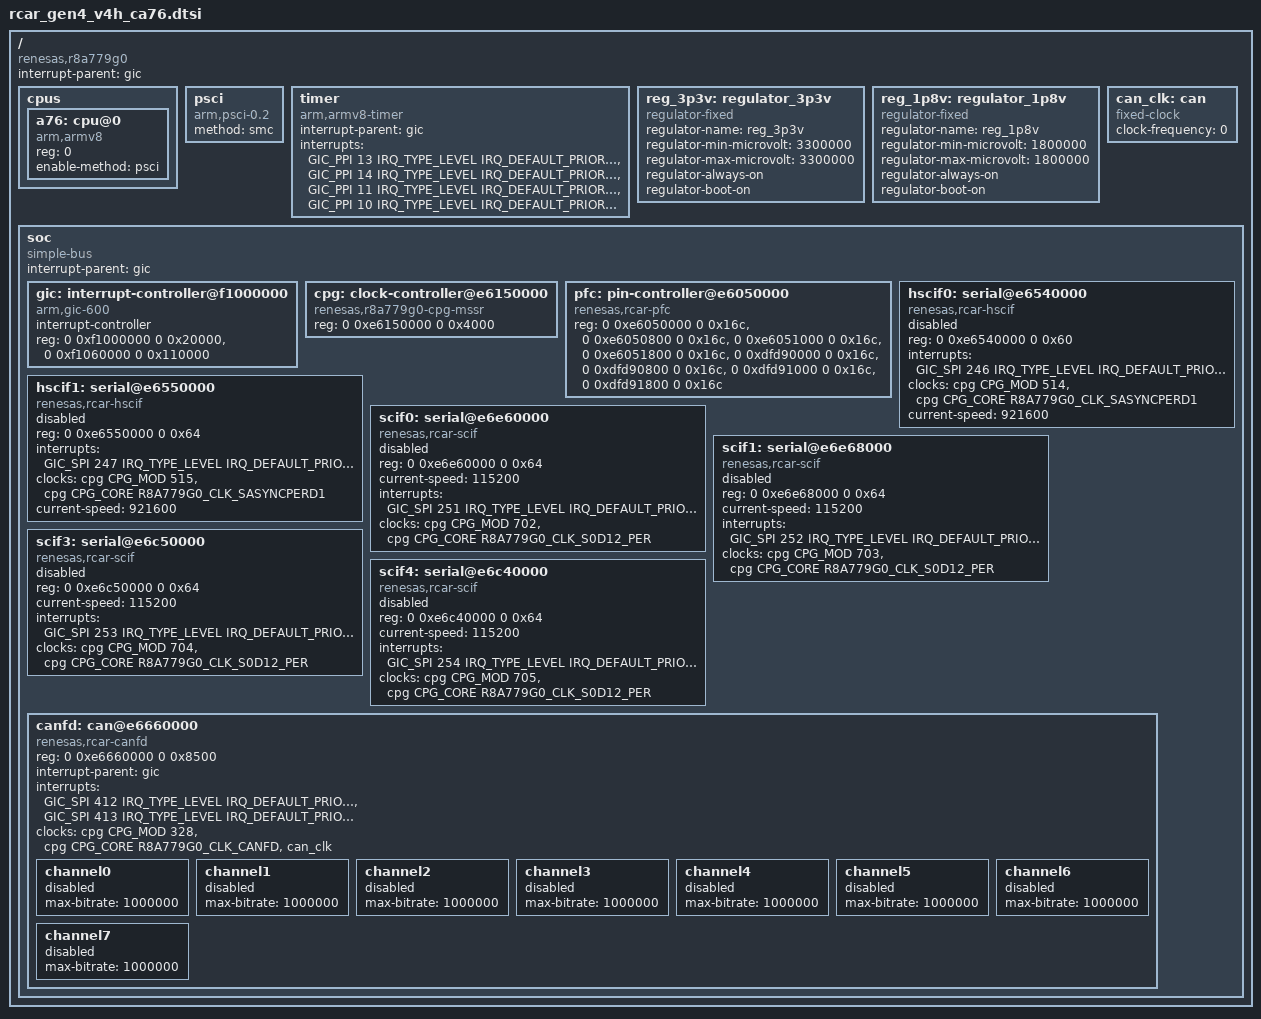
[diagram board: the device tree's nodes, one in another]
/*
 * Copyright (c) 2025 Renesas Electronics Corporation
 *
 * SPDX-License-Identifier: Apache-2.0
 */

#include <mem.h>
#include <arm64/armv8-a.dtsi>
#include <zephyr/dt-bindings/interrupt-controller/arm-gic.h>
#include <zephyr/dt-bindings/clock/renesas_cpg_mssr.h>
#include <zephyr/dt-bindings/clock/r8a779g0_cpg_mssr.h>

/ {
	compatible = "renesas,r8a779g0";
	#address-cells = <2>;
	#size-cells = <2>;
	interrupt-parent = <&gic>;

	cpus {
		#address-cells = <1>;
		#size-cells = <0>;

		a76: cpu@0 {
			device_type = "cpu";
			compatible = "arm,armv8";
			reg = <0>;
			enable-method = "psci";
		};
	};

	psci {
		compatible = "arm,psci-0.2";
		method = "smc";
	};

	timer {
		compatible = "arm,armv8-timer";
		interrupt-parent = <&gic>;
		interrupts = <GIC_PPI 13 IRQ_TYPE_LEVEL IRQ_DEFAULT_PRIORITY>,
			     <GIC_PPI 14 IRQ_TYPE_LEVEL IRQ_DEFAULT_PRIORITY>,
			     <GIC_PPI 11 IRQ_TYPE_LEVEL IRQ_DEFAULT_PRIORITY>,
			     <GIC_PPI 10 IRQ_TYPE_LEVEL IRQ_DEFAULT_PRIORITY>;
	};

	reg_3p3v: regulator_3p3v {
		compatible = "regulator-fixed";
		regulator-name = "reg_3p3v";
		regulator-min-microvolt = <3300000>;
		regulator-max-microvolt = <3300000>;
		regulator-always-on;
		regulator-boot-on;
		status = "okay";
	};

	reg_1p8v: regulator_1p8v {
		compatible = "regulator-fixed";
		regulator-name = "reg_1p8v";
		regulator-min-microvolt = <1800000>;
		regulator-max-microvolt = <1800000>;
		regulator-always-on;
		regulator-boot-on;
		status = "okay";
	};

	can_clk: can {
		compatible = "fixed-clock";
		#clock-cells = <0>;
		clock-frequency = <0>;
	};

	soc: soc {
		compatible = "simple-bus";
		interrupt-parent = <&gic>;

		#address-cells = <2>;
		#size-cells = <2>;
		ranges;

		gic: interrupt-controller@f1000000 {
			compatible = "arm,gic-600", "arm,gic-v3", "arm,gic";
			#interrupt-cells = <4>;
			#address-cells = <0>;
			interrupt-controller;
			reg = <0 0xf1000000 0 0x20000>,
			      <0 0xf1060000 0 0x110000>;
			status = "okay";
		};

		cpg: clock-controller@e6150000 {
			compatible = "renesas,r8a779g0-cpg-mssr";
			reg = <0 0xe6150000 0 0x4000>;
			#clock-cells = <2>;
			#power-domain-cells = <0>;
			#reset-cells = <1>;
		};

		pfc: pin-controller@e6050000 {
			compatible = "renesas,rcar-pfc";
			reg = <0 0xe6050000 0 0x16c>, <0 0xe6050800 0 0x16c>,
			      <0 0xe6051000 0 0x16c>, <0 0xe6051800 0 0x16c>,
			      <0 0xdfd90000 0 0x16c>, <0 0xdfd90800 0 0x16c>,
			      <0 0xdfd91000 0 0x16c>, <0 0xdfd91800 0 0x16c>;
		};

		hscif0: serial@e6540000 {
			compatible = "renesas,rcar-hscif";
			reg = <0 0xe6540000 0 0x60>;
			interrupts = <GIC_SPI 246 IRQ_TYPE_LEVEL IRQ_DEFAULT_PRIORITY>;
			clocks = <&cpg CPG_MOD 514>, <&cpg CPG_CORE R8A779G0_CLK_SASYNCPERD1>;
			current-speed = <921600>;
			status = "disabled";
		};

		hscif1: serial@e6550000 {
			compatible = "renesas,rcar-hscif";
			reg = <0 0xe6550000 0 0x64>;
			interrupts = <GIC_SPI 247 IRQ_TYPE_LEVEL IRQ_DEFAULT_PRIORITY>;
			clocks = <&cpg CPG_MOD 515>, <&cpg CPG_CORE R8A779G0_CLK_SASYNCPERD1>;
			current-speed = <921600>;
			status = "disabled";
		};
		scif0: serial@e6e60000 {
			compatible = "renesas,rcar-scif";
			reg = <0 0xe6e60000 0 0x64>;
			current-speed = <115200>;
			interrupts = <GIC_SPI 251 IRQ_TYPE_LEVEL IRQ_DEFAULT_PRIORITY>;
			clocks = <&cpg CPG_MOD 702>, <&cpg CPG_CORE R8A779G0_CLK_S0D12_PER>;
			status = "disabled";
		};

		scif1: serial@e6e68000 {
			compatible = "renesas,rcar-scif";
			reg = <0 0xe6e68000 0 0x64>;
			current-speed = <115200>;
			interrupts = <GIC_SPI 252 IRQ_TYPE_LEVEL IRQ_DEFAULT_PRIORITY>;
			clocks = <&cpg CPG_MOD 703>, <&cpg CPG_CORE R8A779G0_CLK_S0D12_PER>;
			status = "disabled";
		};

		scif3: serial@e6c50000 {
			compatible = "renesas,rcar-scif";
			reg = <0 0xe6c50000 0 0x64>;
			current-speed = <115200>;
			interrupts = <GIC_SPI 253 IRQ_TYPE_LEVEL IRQ_DEFAULT_PRIORITY>;
			clocks = <&cpg CPG_MOD 704>, <&cpg CPG_CORE R8A779G0_CLK_S0D12_PER>;
			status = "disabled";
		};

		scif4: serial@e6c40000 {
			compatible = "renesas,rcar-scif";
			reg = <0 0xe6c40000 0 0x64>;
			current-speed = <115200>;
			interrupts = <GIC_SPI 254 IRQ_TYPE_LEVEL IRQ_DEFAULT_PRIORITY>;
			clocks = <&cpg CPG_MOD 705>, <&cpg CPG_CORE R8A779G0_CLK_S0D12_PER>;
			status = "disabled";
		};

		canfd: can@e6660000 {
			compatible = "renesas,rcar-canfd";
			reg = <0 0xe6660000 0 0x8500>;
			interrupt-parent = <&gic>;
			interrupts = <GIC_SPI 412 IRQ_TYPE_LEVEL IRQ_DEFAULT_PRIORITY>,
				<GIC_SPI 413 IRQ_TYPE_LEVEL IRQ_DEFAULT_PRIORITY>;

			clocks = <&cpg CPG_MOD 328>,
				 <&cpg CPG_CORE R8A779G0_CLK_CANFD>,
				 <&can_clk>;
			clock-names = "fck", "canfd", "can_clk";
			status = "okay";

			channel0 {
				max-bitrate = <1000000>;
				status = "disabled";
			};

			channel1 {
				max-bitrate = <1000000>;
				status = "disabled";
			};

			channel2 {
				max-bitrate = <1000000>;
				status = "disabled";
			};

			channel3 {
				max-bitrate = <1000000>;
				status = "disabled";
			};

			channel4 {
				max-bitrate = <1000000>;
				status = "disabled";
			};

			channel5 {
				max-bitrate = <1000000>;
				status = "disabled";
			};

			channel6 {
				max-bitrate = <1000000>;
				status = "disabled";
			};

			channel7 {
				status = "disabled";
				max-bitrate = <1000000>;
			};
		};
	};
};
